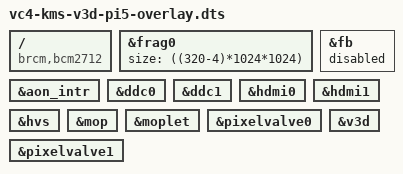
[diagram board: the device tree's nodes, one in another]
// SPDX-License-Identifier: GPL-2.0

#include "cma-overlay.dts"

&frag0 {
	size = <((320-4)*1024*1024)>;
};

/ {
	compatible = "brcm,bcm2712";

	fragment@1 {
		target = <&fb>;
		__overlay__ {
			status = "disabled";
		};
	};

	fragment@2 {
		target = <&aon_intr>;
		__overlay__ {
			status = "okay";
		};
	};

	fragment@3 {
		target = <&ddc0>;
		__overlay__ {
			status = "okay";
		};
	};

	fragment@4 {
		target = <&ddc1>;
		__overlay__ {
			status = "okay";
		};
	};

	fragment@5 {
		target = <&hdmi0>;
		__overlay__ {
			status = "okay";
		};
	};

	fragment@6 {
		target = <&hdmi1>;
		__overlay__ {
			status = "okay";
		};
	};

	fragment@7 {
		target = <&hvs>;
		__overlay__ {
			status = "okay";
		};
	};

	fragment@8 {
		target = <&mop>;
		__overlay__ {
			status = "okay";
		};
	};

	fragment@9 {
		target = <&moplet>;
		__overlay__ {
			status = "okay";
		};
	};

	fragment@10 {
		target = <&pixelvalve0>;
		__overlay__ {
			status = "okay";
		};
	};

	fragment@11 {
		target = <&pixelvalve1>;
		__overlay__ {
			status = "okay";
		};
	};

	fragment@12 {
		target = <&v3d>;
		__overlay__ {
			status = "okay";
		};
	};
};
